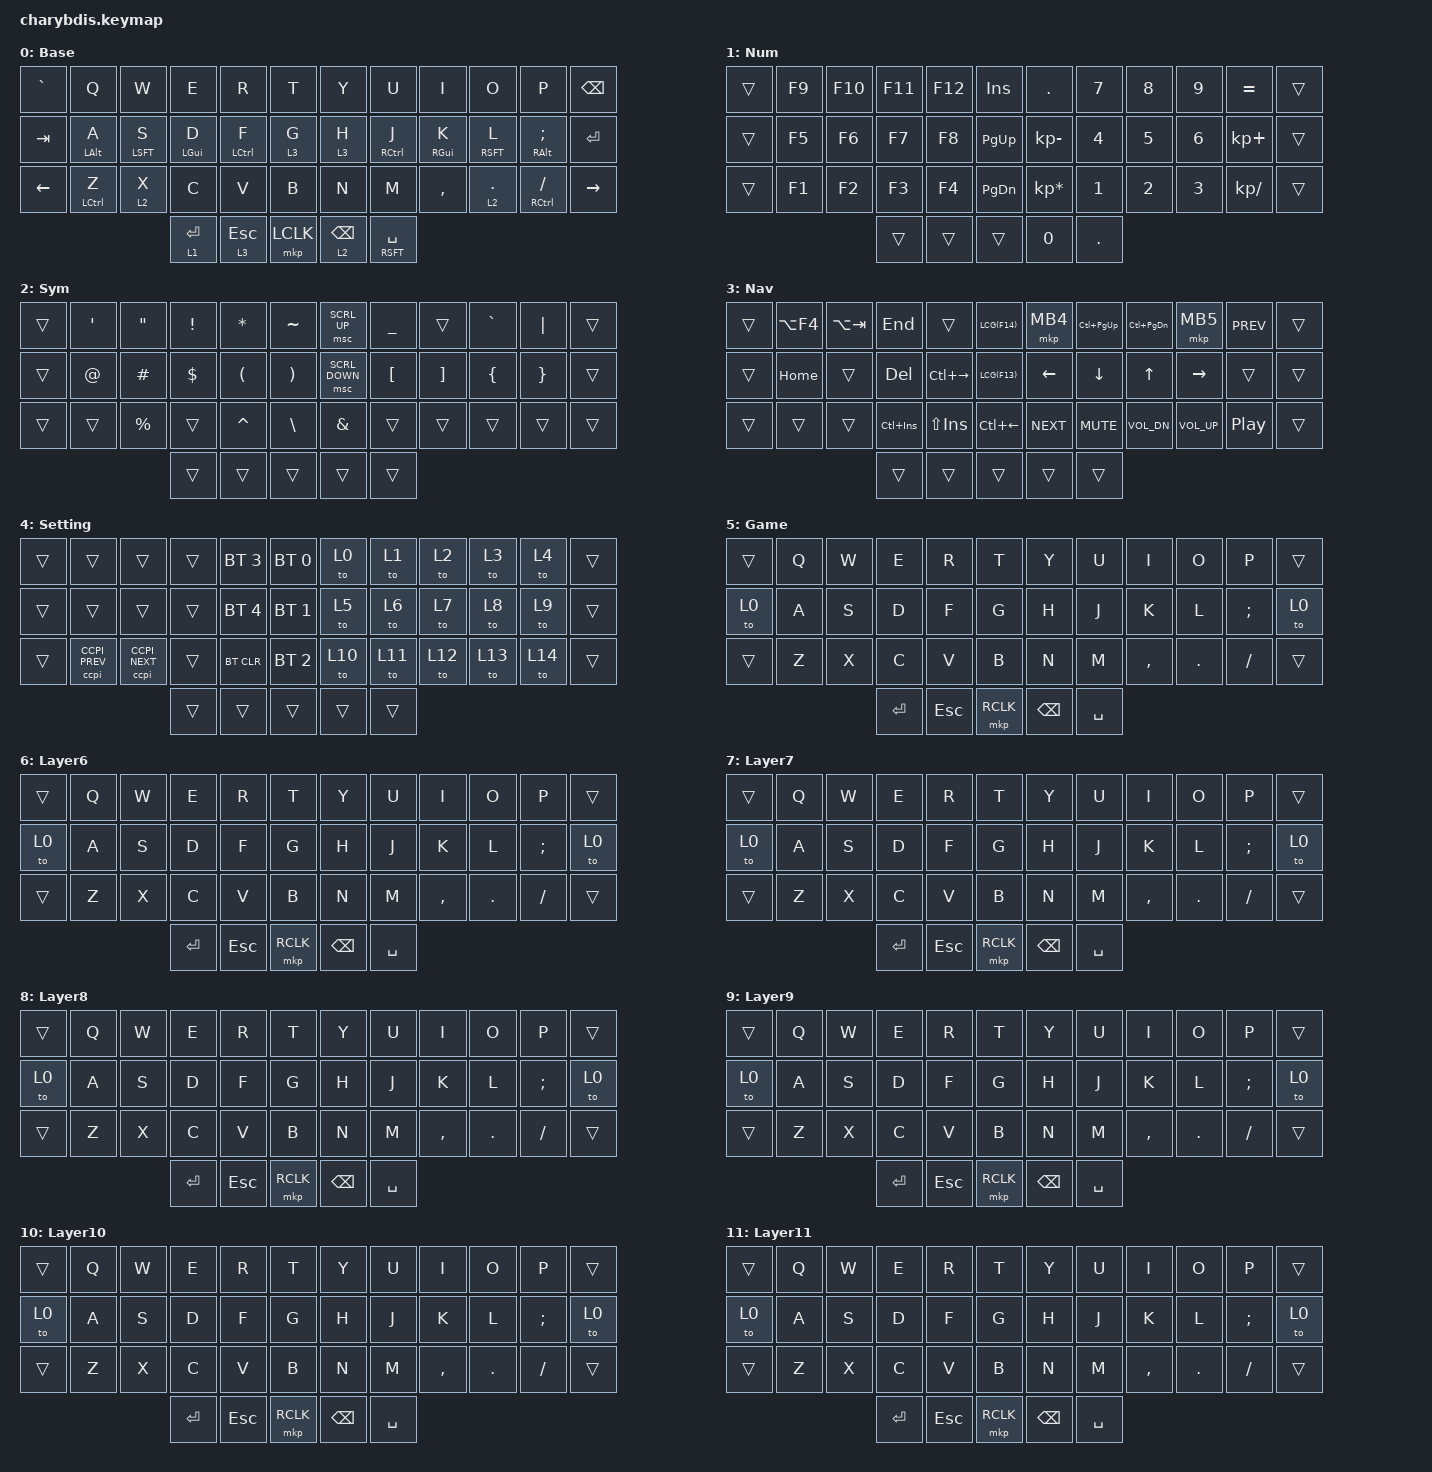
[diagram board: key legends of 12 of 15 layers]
// Copyright (c) 2022 The ZMK Contributors
// SPDX-License-Identifier: MIT

#include <behaviors.dtsi>
#include <dt-bindings/zmk/keys.h>
#include <dt-bindings/zmk/mouse.h>
#include <dt-bindings/zmk/bt.h>
#include <dt-bindings/zmk/cycle_cpi.h>

// Home row mods macro
#define LCS(keycode) APPLY_MODS(MOD_LCTL | MOD_LSFT, keycode)
#define LCG(keycode) APPLY_MODS(MOD_LCTL | MOD_LGUI, keycode)

/ {
/* --- KEYMAP CONFIG --- */
// ╭──────┬──────┬──────┬──────┬──────┬──────╮  ╭──────┬──────┬──────┬──────┬──────┬──────╮
//    00     01     02     03    04      05        06     07     08     09     10     11
// ├──────┼──────┼──────┼──────┼──────┼──────┤  ├──────┼──────┼──────┼──────┼──────┼──────┤
//    12     13     14     15    16      17        18     19     20     21     22     23
// ├──────┼──────┼──────┼──────┼──────┼──────┤  ├──────┼──────┼──────┼──────┼──────┼──────┤
//    24     25     26     27    28      29        30     31     32     33     34     35
// ╰──────┴──────┴──────┼──────┼──────┼──────┤  ├──────┼──────┼──────┴──────┴──────┴──────╯
//                         36     37     38        39     40
//                      ╰──────┴──────┴──────╯  ╰──────┴──────╯
    behaviors {
        ht: hold_tap {
            display-name = "Hold Tap";
            label = "hold_tap";
            compatible = "zmk,behavior-hold-tap";
            #binding-cells = <2>;
            flavor = "balanced";
            tapping-term-ms = <220>;
            quick-tap-ms = <200>;
            // global-quick-tap;
            bindings = <&kp>, <&kp>;
            tap-ms = <20>;
        };
        lt: layer_tap {
            display-name = "Layer Tap";
            compatible = "zmk,behavior-hold-tap";
            label = "LAYER_TAP";
            #binding-cells = <2>;
            // flavor = "balanced";
            tapping-term-ms = <200>;
            quick-tap-ms = <200>;
            // global-quick-tap;
            bindings = <&mo>, <&kp>;
            tap-ms = <20>;
        };
        ccpi: ccpi {
            compatible = "zmk,behavior-cycle-cpi";
            #binding-cells = <1>;
            device = <&trackball>;
            cpis = <200 400 600 800 1000 1600 2400 3200>;
            default-cpi-index = <2>;
            display-name = "CPI";
        };
    };

    combos {
        compatible = "zmk,combos";
        combo_tab {
            timeout-ms = <50>;
            key-positions = <3 4>;
            bindings = <&kp TAB>;
        };
        combo_left_click {
            bindings = <&mkp LCLK>;
            key-positions = <25 26>;
        };
        combo_middle_click {
            bindings = <&mkp MCLK>;
            key-positions = <26 27>;
        };
        combo_right_click {
            bindings = <&mkp RCLK>;
            key-positions = <27 28>;
        };
        combo_left_click_r {
            bindings = <&mkp LCLK>;
            key-positions = <31 32>;
        };
        combo_middle_click_r {
            bindings = <&mkp MCLK>;
            key-positions = <32 33>;
        };
        combo_right_click_r {
            bindings = <&mkp RCLK>;
            key-positions = <33 34>;
        };
        combo_power {
            bindings = <&kp K_POWER>;
            key-positions = <12 24>;
        };
    };

    conditional_layers {
        compatible = "zmk,conditional-layers";
        SETTING {
            if-layers = <2 3>;
            then-layer = <4>;
        };
    };

    keymap {
        compatible = "zmk,keymap";
        BASE {
            display-name = "Base";
            bindings = <
// ╭───────────────┬───────────────┬───────────────┬───────────────┬───────────────┬──────────────╮  ╭───────────────┬───────────────┬───────────────┬───────────────┬───────────────┬──────────────╮
    &kp GRAVE        &kp Q           &kp W           &kp E           &kp R           &kp T             &kp Y           &kp U           &kp I           &kp O           &kp P           &kp BSPC
// ├───────────────┼───────────────┼───────────────┼───────────────┼───────────────┼──────────────┤  ├───────────────┼───────────────┼───────────────┼───────────────┼───────────────┼──────────────┤
    &kp TAB          &ht LALT A      &ht LSFT S      &ht LGUI D      &ht LCTL F      &lt 3 G           &lt 3 H         &ht RCTRL J     &ht RGUI K      &ht RSFT L      &ht RALT SEMI   &kp ENTER
// ├───────────────┼───────────────┼───────────────┼───────────────┼───────────────┼──────────────┤  ├───────────────┼───────────────┼───────────────┼───────────────┼───────────────┼──────────────┤
    &kp LEFT         &ht LCTL Z      &lt 2 X         &kp C           &kp V           &kp B             &kp N           &kp M           &kp COMMA       &lt 2 DOT       &ht RCTL FSLH   &kp RIGHT
// ╰───────────────┴───────────────┴───────────────┼───────────────┼───────────────┼──────────────┤  ├───────────────┼───────────────┼───────────────┴───────────────┴───────────────┴──────────────╯
                                                     &lt 1 ENTER     &lt 3 ESC       &mkp LCLK         &lt 2 BSPC      &ht RSFT SPC 
//                                                 ╰───────────────┴───────────────┴──────────────╯  ╰───────────────┴───────────────╯
            >;
        };

        NUM {
            display-name = "Num";
            bindings = <
// ╭───────────────┬───────────────┬───────────────┬───────────────┬───────────────┬──────────────╮  ╭───────────────┬───────────────┬───────────────┬───────────────┬───────────────┬──────────────╮
     &trans          &kp F9          &kp F10         &kp F11         &kp F12         &kp INS           &kp DOT         &kp N7          &kp N8          &kp N9          &kp EQUAL       &trans
// ├───────────────┼───────────────┼───────────────┼───────────────┼───────────────┼──────────────┤  ├───────────────┼───────────────┼───────────────┼───────────────┼───────────────┼──────────────┤
     &trans          &kp F5          &kp F6          &kp F7          &kp F8          &kp PG_UP         &kp KP_MINUS    &kp N4          &kp N5          &kp N6          &kp KP_PLUS     &trans
// ├───────────────┼───────────────┼───────────────┼───────────────┼───────────────┼──────────────┤  ├───────────────┼───────────────┼───────────────┼───────────────┼───────────────┼──────────────┤
     &trans          &kp F1          &kp F2          &kp F3          &kp F4          &kp PG_DN         &kp KP_MULTIPLY &kp N1          &kp N2          &kp N3          &kp KP_DIVIDE   &trans
// ╰───────────────┴───────────────┴───────────────┼───────────────┼───────────────┼──────────────┤  ├───────────────┼───────────────┼───────────────┴───────────────┴───────────────┴──────────────╯
                                                     &trans          &trans          &trans            &kp N0          &kp DOT 
//                                                 ╰───────────────┴───────────────┴──────────────╯  ╰───────────────┴───────────────╯
            >;
        };

        SYM {
            display-name = "Sym";
            bindings = <
// ╭───────────────┬───────────────┬───────────────┬───────────────┬───────────────┬──────────────╮  ╭───────────────┬───────────────┬───────────────┬───────────────┬───────────────┬──────────────╮
     &trans          &kp SQT         &kp DQT         &kp EXCL        &kp STAR        &kp TILDE         &msc SCRL_UP    &kp UNDER       &trans          &kp GRAVE       &kp PIPE        &trans 
// ├───────────────┼───────────────┼───────────────┼───────────────┼───────────────┼──────────────┤  ├───────────────┼───────────────┼───────────────┼───────────────┼───────────────┼──────────────┤
     &trans          &kp AT          &kp HASH        &kp DLLR        &kp LPAR        &kp RPAR          &msc SCRL_DOWN  &kp LBKT        &kp RBKT        &kp LBRC        &kp RBRC        &trans 
// ├───────────────┼───────────────┼───────────────┼───────────────┼───────────────┼──────────────┤  ├───────────────┼───────────────┼───────────────┼───────────────┼───────────────┼──────────────┤
     &trans          &trans          &kp PRCNT       &trans          &kp CARET       &kp BSLH          &kp AMPS        &trans          &trans          &trans          &trans          &trans
// ╰───────────────┴───────────────┴───────────────┼───────────────┼───────────────┼──────────────┤  ├───────────────┼───────────────┼───────────────┴───────────────┴───────────────┴──────────────╯
                                                     &trans          &trans          &trans            &trans          &trans
//                                                 ╰───────────────┴───────────────┴──────────────╯  ╰───────────────┴───────────────╯
            >;
        };

        NAV {
            display-name = "Nav";
            bindings = <
// ╭───────────────┬───────────────┬───────────────┬───────────────┬───────────────┬──────────────╮  ╭───────────────┬───────────────┬───────────────┬───────────────┬───────────────┬──────────────╮
     &trans          &kp LA(F4)      &kp LA(TAB)     &kp END         &trans          &kp LCG(F14)      &mkp MB4        &kp LC(PG_UP)   &kp LC(PG_DN)   &mkp MB5        &kp C_PREV      &trans
// ├───────────────┼───────────────┼───────────────┼───────────────┼───────────────┼──────────────┤  ├───────────────┼───────────────┼───────────────┼───────────────┼───────────────┼──────────────┤
     &trans          &kp HOME        &trans          &kp DEL         &kp LC(RIGHT)   &kp LCG(F13)      &kp LEFT        &kp DOWN        &kp UP          &kp RIGHT       &trans          &trans
// ├───────────────┼───────────────┼───────────────┼───────────────┼───────────────┼──────────────┤  ├───────────────┼───────────────┼───────────────┼───────────────┼───────────────┼──────────────┤
     &trans          &trans          &trans          &kp LC(INS)     &kp LS(INS)     &kp LC(LEFT)      &kp C_NEXT      &kp C_MUTE      &kp C_VOL_DN    &kp C_VOL_UP    &kp C_PP        &trans
// ╰───────────────┴───────────────┴───────────────┼───────────────┼───────────────┼──────────────┤  ├───────────────┼───────────────┼───────────────┴───────────────┴───────────────┴──────────────╯
                                                     &trans          &trans          &trans            &trans          &trans
//                                                 ╰───────────────┴───────────────┴──────────────╯  ╰───────────────┴───────────────╯
            >;
        };

        SETTING {
            display-name = "Setting";
            bindings = <
// ╭───────────────┬───────────────┬───────────────┬───────────────┬───────────────┬──────────────╮  ╭───────────────┬───────────────┬───────────────┬───────────────┬───────────────┬──────────────╮
     &trans          &trans          &trans          &trans          &bt BT_SEL 3    &bt BT_SEL 0      &to 0           &to 1           &to 2           &to 3           &to 4           &trans
// ├───────────────┼───────────────┼───────────────┼───────────────┼───────────────┼──────────────┤  ├───────────────┼───────────────┼───────────────┼───────────────┼───────────────┼──────────────┤
     &trans          &trans          &trans          &trans          &bt BT_SEL 4    &bt BT_SEL 1      &to 5           &to 6           &to 7           &to 8           &to 9           &trans
// ├───────────────┼───────────────┼───────────────┼───────────────┼───────────────┼──────────────┤  ├───────────────┼───────────────┼───────────────┼───────────────┼───────────────┼──────────────┤
     &trans          &ccpi CCPI_PREV &ccpi CCPI_NEXT &trans          &bt BT_CLR      &bt BT_SEL 2      &to 10          &to 11          &to 12          &to 13          &to 14          &trans
// ╰───────────────┴───────────────┴───────────────┼───────────────┼───────────────┼──────────────┤  ├───────────────┼───────────────┼───────────────┴───────────────┴───────────────┴──────────────╯
                                                     &trans          &trans          &trans            &trans          &trans
//                                                 ╰───────────────┴───────────────┴──────────────╯  ╰───────────────┴───────────────╯
            >;
        };

        GAME {
            display-name = "Game";
            bindings = <
// ╭───────────────┬───────────────┬───────────────┬───────────────┬───────────────┬──────────────╮  ╭───────────────┬───────────────┬───────────────┬───────────────┬───────────────┬──────────────╮
     &trans          &kp Q           &kp W           &kp E           &kp R           &kp T             &kp Y           &kp U           &kp I           &kp O           &kp P           &trans
// ├───────────────┼───────────────┼───────────────┼───────────────┼───────────────┼──────────────┤  ├───────────────┼───────────────┼───────────────┼───────────────┼───────────────┼──────────────┤
     &to 0           &kp A           &kp S           &kp D           &kp F           &kp G             &kp H           &kp J           &kp K           &kp L           &kp SEMI        &to 0
// ├───────────────┼───────────────┼───────────────┼───────────────┼───────────────┼──────────────┤  ├───────────────┼───────────────┼───────────────┼───────────────┼───────────────┼──────────────┤
     &trans          &kp Z           &kp X           &kp C           &kp V           &kp B             &kp N           &kp M           &kp COMMA       &kp DOT         &kp FSLH        &trans
// ╰───────────────┴───────────────┴───────────────┼───────────────┼───────────────┼──────────────┤  ├───────────────┼───────────────┼───────────────┴───────────────┴───────────────┴──────────────╯
                                                     &kp ENTER       &kp ESC         &mkp RCLK         &kp BSPC        &kp SPC 
//                                                 ╰───────────────┴───────────────┴──────────────╯  ╰───────────────┴───────────────╯
            >;
        };

        LAYER6 {
            display-name = "Layer6";
            bindings = <
// ╭───────────────┬───────────────┬───────────────┬───────────────┬───────────────┬──────────────╮  ╭───────────────┬───────────────┬───────────────┬───────────────┬───────────────┬──────────────╮
     &trans          &kp Q           &kp W           &kp E           &kp R           &kp T             &kp Y           &kp U           &kp I           &kp O           &kp P           &trans
// ├───────────────┼───────────────┼───────────────┼───────────────┼───────────────┼──────────────┤  ├───────────────┼───────────────┼───────────────┼───────────────┼───────────────┼──────────────┤
     &to 0           &kp A           &kp S           &kp D           &kp F           &kp G             &kp H           &kp J           &kp K           &kp L           &kp SEMI        &to 0
// ├───────────────┼───────────────┼───────────────┼───────────────┼───────────────┼──────────────┤  ├───────────────┼───────────────┼───────────────┼───────────────┼───────────────┼──────────────┤
     &trans          &kp Z           &kp X           &kp C           &kp V           &kp B             &kp N           &kp M           &kp COMMA       &kp DOT         &kp FSLH        &trans
// ╰───────────────┴───────────────┴───────────────┼───────────────┼───────────────┼──────────────┤  ├───────────────┼───────────────┼───────────────┴───────────────┴───────────────┴──────────────╯
                                                     &kp ENTER       &kp ESC         &mkp RCLK         &kp BSPC        &kp SPC 
//                                                 ╰───────────────┴───────────────┴──────────────╯  ╰───────────────┴───────────────╯
            >;
        };

        LAYER7 {
            display-name = "Layer7";
            bindings = <
// ╭───────────────┬───────────────┬───────────────┬───────────────┬───────────────┬──────────────╮  ╭───────────────┬───────────────┬───────────────┬───────────────┬───────────────┬──────────────╮
     &trans          &kp Q           &kp W           &kp E           &kp R           &kp T             &kp Y           &kp U           &kp I           &kp O           &kp P           &trans
// ├───────────────┼───────────────┼───────────────┼───────────────┼───────────────┼──────────────┤  ├───────────────┼───────────────┼───────────────┼───────────────┼───────────────┼──────────────┤
     &to 0           &kp A           &kp S           &kp D           &kp F           &kp G             &kp H           &kp J           &kp K           &kp L           &kp SEMI        &to 0
// ├───────────────┼───────────────┼───────────────┼───────────────┼───────────────┼──────────────┤  ├───────────────┼───────────────┼───────────────┼───────────────┼───────────────┼──────────────┤
     &trans          &kp Z           &kp X           &kp C           &kp V           &kp B             &kp N           &kp M           &kp COMMA       &kp DOT         &kp FSLH        &trans
// ╰───────────────┴───────────────┴───────────────┼───────────────┼───────────────┼──────────────┤  ├───────────────┼───────────────┼───────────────┴───────────────┴───────────────┴──────────────╯
                                                     &kp ENTER       &kp ESC         &mkp RCLK         &kp BSPC        &kp SPC 
//                                                 ╰───────────────┴───────────────┴──────────────╯  ╰───────────────┴───────────────╯
            >;
        };

        LAYER8 {
            display-name = "Layer8";
            bindings = <
// ╭───────────────┬───────────────┬───────────────┬───────────────┬───────────────┬──────────────╮  ╭───────────────┬───────────────┬───────────────┬───────────────┬───────────────┬──────────────╮
     &trans          &kp Q           &kp W           &kp E           &kp R           &kp T             &kp Y           &kp U           &kp I           &kp O           &kp P           &trans
// ├───────────────┼───────────────┼───────────────┼───────────────┼───────────────┼──────────────┤  ├───────────────┼───────────────┼───────────────┼───────────────┼───────────────┼──────────────┤
     &to 0           &kp A           &kp S           &kp D           &kp F           &kp G             &kp H           &kp J           &kp K           &kp L           &kp SEMI        &to 0
// ├───────────────┼───────────────┼───────────────┼───────────────┼───────────────┼──────────────┤  ├───────────────┼───────────────┼───────────────┼───────────────┼───────────────┼──────────────┤
     &trans          &kp Z           &kp X           &kp C           &kp V           &kp B             &kp N           &kp M           &kp COMMA       &kp DOT         &kp FSLH        &trans
// ╰───────────────┴───────────────┴───────────────┼───────────────┼───────────────┼──────────────┤  ├───────────────┼───────────────┼───────────────┴───────────────┴───────────────┴──────────────╯
                                                     &kp ENTER       &kp ESC         &mkp RCLK         &kp BSPC        &kp SPC 
//                                                 ╰───────────────┴───────────────┴──────────────╯  ╰───────────────┴───────────────╯
            >;
        };

        LAYER9 {
            display-name = "Layer9";
            bindings = <
// ╭───────────────┬───────────────┬───────────────┬───────────────┬───────────────┬──────────────╮  ╭───────────────┬───────────────┬───────────────┬───────────────┬───────────────┬──────────────╮
     &trans          &kp Q           &kp W           &kp E           &kp R           &kp T             &kp Y           &kp U           &kp I           &kp O           &kp P           &trans
// ├───────────────┼───────────────┼───────────────┼───────────────┼───────────────┼──────────────┤  ├───────────────┼───────────────┼───────────────┼───────────────┼───────────────┼──────────────┤
     &to 0           &kp A           &kp S           &kp D           &kp F           &kp G             &kp H           &kp J           &kp K           &kp L           &kp SEMI        &to 0
// ├───────────────┼───────────────┼───────────────┼───────────────┼───────────────┼──────────────┤  ├───────────────┼───────────────┼───────────────┼───────────────┼───────────────┼──────────────┤
     &trans          &kp Z           &kp X           &kp C           &kp V           &kp B             &kp N           &kp M           &kp COMMA       &kp DOT         &kp FSLH        &trans
// ╰───────────────┴───────────────┴───────────────┼───────────────┼───────────────┼──────────────┤  ├───────────────┼───────────────┼───────────────┴───────────────┴───────────────┴──────────────╯
                                                     &kp ENTER       &kp ESC         &mkp RCLK         &kp BSPC        &kp SPC 
//                                                 ╰───────────────┴───────────────┴──────────────╯  ╰───────────────┴───────────────╯
            >;
        };

        LAYER10 {
            display-name = "Layer10";
            bindings = <
// ╭───────────────┬───────────────┬───────────────┬───────────────┬───────────────┬──────────────╮  ╭───────────────┬───────────────┬───────────────┬───────────────┬───────────────┬──────────────╮
     &trans          &kp Q           &kp W           &kp E           &kp R           &kp T             &kp Y           &kp U           &kp I           &kp O           &kp P           &trans
// ├───────────────┼───────────────┼───────────────┼───────────────┼───────────────┼──────────────┤  ├───────────────┼───────────────┼───────────────┼───────────────┼───────────────┼──────────────┤
     &to 0           &kp A           &kp S           &kp D           &kp F           &kp G             &kp H           &kp J           &kp K           &kp L           &kp SEMI        &to 0
// ├───────────────┼───────────────┼───────────────┼───────────────┼───────────────┼──────────────┤  ├───────────────┼───────────────┼───────────────┼───────────────┼───────────────┼──────────────┤
     &trans          &kp Z           &kp X           &kp C           &kp V           &kp B             &kp N           &kp M           &kp COMMA       &kp DOT         &kp FSLH        &trans
// ╰───────────────┴───────────────┴───────────────┼───────────────┼───────────────┼──────────────┤  ├───────────────┼───────────────┼───────────────┴───────────────┴───────────────┴──────────────╯
                                                     &kp ENTER       &kp ESC         &mkp RCLK         &kp BSPC        &kp SPC 
//                                                 ╰───────────────┴───────────────┴──────────────╯  ╰───────────────┴───────────────╯
            >;
        };

        LAYER11 {
            display-name = "Layer11";
            bindings = <
// ╭───────────────┬───────────────┬───────────────┬───────────────┬───────────────┬──────────────╮  ╭───────────────┬───────────────┬───────────────┬───────────────┬───────────────┬──────────────╮
     &trans          &kp Q           &kp W           &kp E           &kp R           &kp T             &kp Y           &kp U           &kp I           &kp O           &kp P           &trans
// ├───────────────┼───────────────┼───────────────┼───────────────┼───────────────┼──────────────┤  ├───────────────┼───────────────┼───────────────┼───────────────┼───────────────┼──────────────┤
     &to 0           &kp A           &kp S           &kp D           &kp F           &kp G             &kp H           &kp J           &kp K           &kp L           &kp SEMI        &to 0
// ├───────────────┼───────────────┼───────────────┼───────────────┼───────────────┼──────────────┤  ├───────────────┼───────────────┼───────────────┼───────────────┼───────────────┼──────────────┤
     &trans          &kp Z           &kp X           &kp C           &kp V           &kp B             &kp N           &kp M           &kp COMMA       &kp DOT         &kp FSLH        &trans
// ╰───────────────┴───────────────┴───────────────┼───────────────┼───────────────┼──────────────┤  ├───────────────┼───────────────┼───────────────┴───────────────┴───────────────┴──────────────╯
                                                     &kp ENTER       &kp ESC         &mkp RCLK         &kp BSPC        &kp SPC 
//                                                 ╰───────────────┴───────────────┴──────────────╯  ╰───────────────┴───────────────╯
            >;
        };

        LAYER12 {
            display-name = "Layer12";
            bindings = <
// ╭───────────────┬───────────────┬───────────────┬───────────────┬───────────────┬──────────────╮  ╭───────────────┬───────────────┬───────────────┬───────────────┬───────────────┬──────────────╮
     &trans          &kp Q           &kp W           &kp E           &kp R           &kp T             &kp Y           &kp U           &kp I           &kp O           &kp P           &trans
// ├───────────────┼───────────────┼───────────────┼───────────────┼───────────────┼──────────────┤  ├───────────────┼───────────────┼───────────────┼───────────────┼───────────────┼──────────────┤
     &to 0           &kp A           &kp S           &kp D           &kp F           &kp G             &kp H           &kp J           &kp K           &kp L           &kp SEMI        &to 0
// ├───────────────┼───────────────┼───────────────┼───────────────┼───────────────┼──────────────┤  ├───────────────┼───────────────┼───────────────┼───────────────┼───────────────┼──────────────┤
     &trans          &kp Z           &kp X           &kp C           &kp V           &kp B             &kp N           &kp M           &kp COMMA       &kp DOT         &kp FSLH        &trans
// ╰───────────────┴───────────────┴───────────────┼───────────────┼───────────────┼──────────────┤  ├───────────────┼───────────────┼───────────────┴───────────────┴───────────────┴──────────────╯
                                                     &kp ENTER       &kp ESC         &mkp RCLK         &kp BSPC        &kp SPC 
//                                                 ╰───────────────┴───────────────┴──────────────╯  ╰───────────────┴───────────────╯
            >;
        };

        LAYER13 {
            display-name = "Layer13";
            bindings = <
// ╭───────────────┬───────────────┬───────────────┬───────────────┬───────────────┬──────────────╮  ╭───────────────┬───────────────┬───────────────┬───────────────┬───────────────┬──────────────╮
     &trans          &kp Q           &kp W           &kp E           &kp R           &kp T             &kp Y           &kp U           &kp I           &kp O           &kp P           &trans
// ├───────────────┼───────────────┼───────────────┼───────────────┼───────────────┼──────────────┤  ├───────────────┼───────────────┼───────────────┼───────────────┼───────────────┼──────────────┤
     &to 0           &kp A           &kp S           &kp D           &kp F           &kp G             &kp H           &kp J           &kp K           &kp L           &kp SEMI        &to 0
// ├───────────────┼───────────────┼───────────────┼───────────────┼───────────────┼──────────────┤  ├───────────────┼───────────────┼───────────────┼───────────────┼───────────────┼──────────────┤
     &trans          &kp Z           &kp X           &kp C           &kp V           &kp B             &kp N           &kp M           &kp COMMA       &kp DOT         &kp FSLH        &trans
// ╰───────────────┴───────────────┴───────────────┼───────────────┼───────────────┼──────────────┤  ├───────────────┼───────────────┼───────────────┴───────────────┴───────────────┴──────────────╯
                                                     &kp ENTER       &kp ESC         &mkp RCLK         &kp BSPC        &kp SPC 
//                                                 ╰───────────────┴───────────────┴──────────────╯  ╰───────────────┴───────────────╯
            >;
        };

        LAYER14 {
            display-name = "Layer14";
            bindings = <
// ╭───────────────┬───────────────┬───────────────┬───────────────┬───────────────┬──────────────╮  ╭───────────────┬───────────────┬───────────────┬───────────────┬───────────────┬──────────────╮
     &trans          &kp Q           &kp W           &kp E           &kp R           &kp T             &kp Y           &kp U           &kp I           &kp O           &kp P           &trans
// ├───────────────┼───────────────┼───────────────┼───────────────┼───────────────┼──────────────┤  ├───────────────┼───────────────┼───────────────┼───────────────┼───────────────┼──────────────┤
     &to 0           &kp A           &kp S           &kp D           &kp F           &kp G             &kp H           &kp J           &kp K           &kp L           &kp SEMI        &to 0
// ├───────────────┼───────────────┼───────────────┼───────────────┼───────────────┼──────────────┤  ├───────────────┼───────────────┼───────────────┼───────────────┼───────────────┼──────────────┤
     &trans          &kp Z           &kp X           &kp C           &kp V           &kp B             &kp N           &kp M           &kp COMMA       &kp DOT         &kp FSLH        &trans
// ╰───────────────┴───────────────┴───────────────┼───────────────┼───────────────┼──────────────┤  ├───────────────┼───────────────┼───────────────┴───────────────┴───────────────┴──────────────╯
                                                     &kp ENTER       &kp ESC         &mkp RCLK         &kp BSPC        &kp SPC 
//                                                 ╰───────────────┴───────────────┴──────────────╯  ╰───────────────┴───────────────╯
            >;
        };
    };
};
